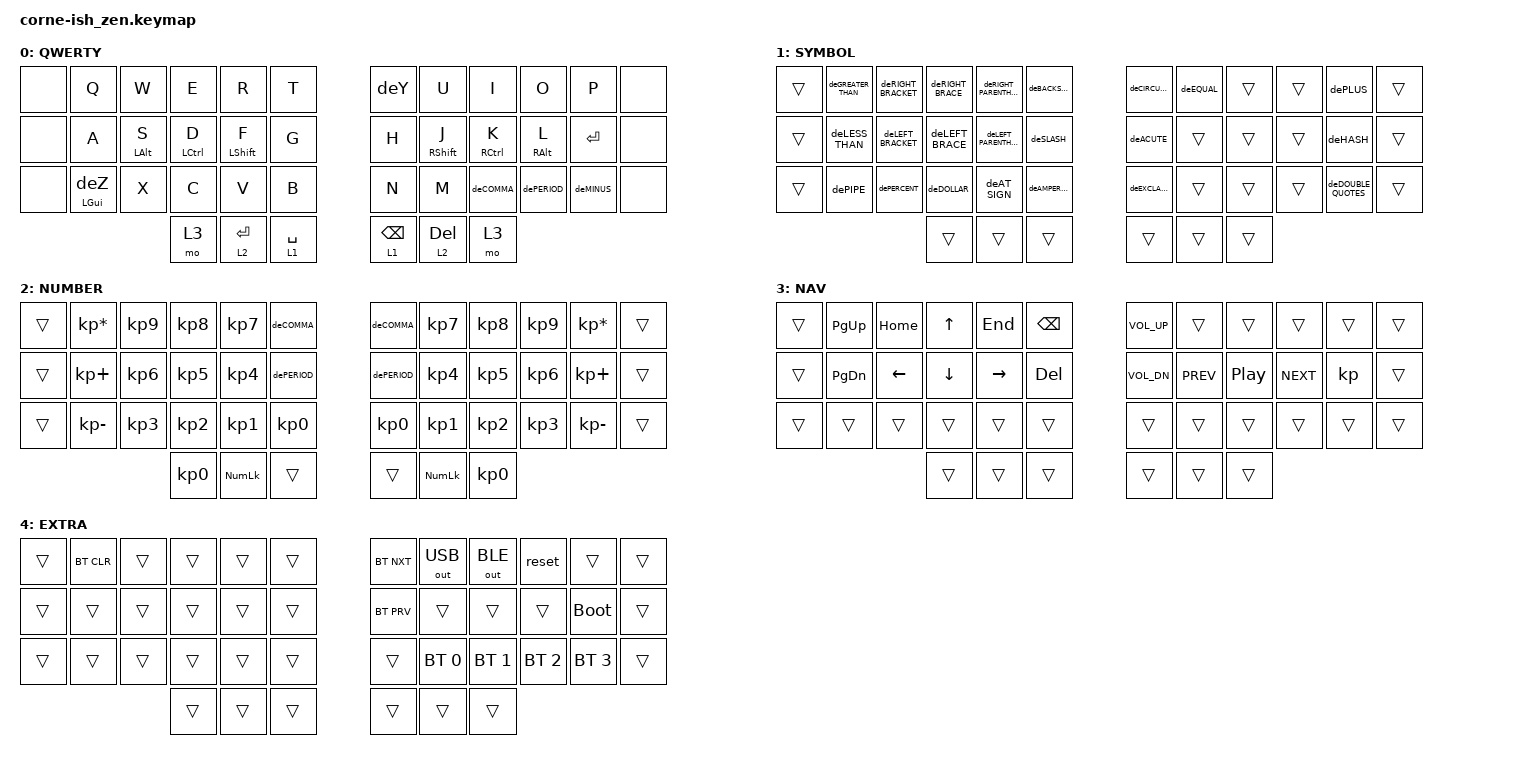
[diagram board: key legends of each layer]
/*
*
* Copyright (c) 2021 Darryl deHaan
* SPDX-License-Identifier: MIT
*
*/

#include <behaviors.dtsi>
#include "language_german.dtsi"
#include <dt-bindings/zmk/keys.h>
#include <dt-bindings/zmk/bt.h>
#include <dt-bindings/zmk/outputs.h>

/ {

	behaviors {
		hm: homerow_mods {
			compatible = "zmk,behavior-hold-tap";
			label = "homerow mods";
			#binding-cells = <2>;
			tapping_term_ms = <200>;
			flavor = "tap-preferred";
			bindings = <&kp>, <&kp>;
		};
	};


	combos {
        compatible = "zmk,combos";
        combo_nav {
            timeout-ms = <40>;
            key-positions = <37 38>;
            bindings = <&tog 3>;
        };
        combo_extra {
            timeout-ms = <40>;
            key-positions = <9 10>;
            bindings = <&tog 4>;
        };

        combo_ue {
            timeout-ms = <40>;
            key-positions = <7 3>;
            bindings = <&kp deUE>;
        };
    	combo_oe {
            timeout-ms = <40>;
            key-positions = <9 3>;
            bindings = <&kp deOE>;
        };
	    combo_ae {
            timeout-ms = <40>;
            key-positions = <13 3>;
            bindings = <&kp deAE>;
        };
        combo_ss {
            timeout-ms = <40>;
            key-positions = <14 15>;
            bindings = <&kp deESZETT>;
        }; 

        combo_esc {
            timeout-ms = <40>;
            key-positions = <16 17>;
            bindings = <&kp ESCAPE>;
        };
        combo_tab {
            timeout-ms = <40>;
            key-positions = <28 29>;
            bindings = <&kp TAB>;
        };

        combo_F1 {
            timeout-ms = <40>;
            key-positions = <1 13>;
            bindings = <&kp F1>;
        };
        combo_F2 {
            timeout-ms = <40>;
            key-positions = <2 14>;
            bindings = <&kp F2>;
        };
        combo_F3 {
            timeout-ms = <40>;
            key-positions = <3 15>;
            bindings = <&kp F3>;
        };
        combo_F4 {
            timeout-ms = <40>;
            key-positions = <4 16>;
            bindings = <&kp F4>;
        };
        combo_F5 {
            timeout-ms = <40>;
            key-positions = <5 17>;
            bindings = <&kp F5>;
        };
        combo_F6 {
            timeout-ms = <40>;
            key-positions = <6 18>;
            bindings = <&kp F6>;
        };
        combo_F7 {
            timeout-ms = <40>;
            key-positions = <7 19>;
            bindings = <&kp F7>;
        };
        combo_F8 {
            timeout-ms = <40>;
            key-positions = <8 20>;
            bindings = <&kp F8>;
        };
        combo_F9 {
            timeout-ms = <40>;
            key-positions = <9 21>;
            bindings = <&kp F1>;
        };
        combo_F10 {
            timeout-ms = <40>;
            key-positions = <10 22>;
            bindings = <&kp F10>;
        };
        combo_F11 {
            timeout-ms = <40>;
            key-positions = <1 2>;
            bindings = <&kp F11>;
        };
        combo_F12 {
            timeout-ms = <40>;
            key-positions = <9 10>;
            bindings = <&kp F12>;
        };

    };
    
        keymap {
                compatible = "zmk,keymap";

                default_layer {
                        label = "QWERTY";
// -----------------------------------------------------------------------------------------
// |      |  Q  |  W  |  E  |  R  |  T  |   |  Y  |  U   |  I  |  O  |  P  |      |
// |      |  A  |  S  |  D  |  F  |  G  |   |  H  |  J   |  K  |  L  |  ;  |      |
// |      |  Z  |  X  |  C  |  V  |  B  |   |  N  |  M   |  ,  |  .  |  /  |      |
//                    |     | LWR | SPC |   | ENT | RSE  |     |
                        bindings = <
// 0     1            2          3           4           5             /**/   6          7           8           9            10          11                   
   &none &kp Q        &kp W      &kp E       &kp R       &kp T         /**/   &kp deY    &kp U       &kp I       &kp O        &kp P       &none
// 12    13           14         15          16          17            /**/   18         19          20          21           22          23
   &none &kp A        &hm LALT S &hm LCTRL D &hm LSHFT F &kp G         /**/   &kp H      &hm RSHFT J &hm RCTRL K &hm RALT L   &kp RET     &none
// 24    25           26         27          28          29            /**/   30         31          32          33           34          35 
   &none &hm LGUI deZ &kp X      &kp C       &kp V       &kp B         /**/   &kp N      &kp M       &kp deCOMMA &kp dePERIOD &kp deMINUS &none
//                               36          37          38            /**/   39         40          41    
                                 &mo 3       &lt 2 RET   &lt 1 SPACE   /**/   &lt 1 BSPC &lt 2 DEL   &mo 3
                        >;
                };
                symbol {
                        label = "SYMBOL";
// -----------------------------------------------------------------------------------------
// |      |  >  |  ]  |  }  |  )  |  \  |   |   ^  |     |     |     |  +  |     |
// |      |  <  |  [  |  {  |  (  |  /  |   |   ´  |     |     |     |  #  |     |
// |      |  |  |  %  |  $  |  @  |  &  |   |   !  |     |     |     |     |     |
//                    |     |     |     |   |      |     |     |
                        bindings = <
   &trans &kp deGREATER_THAN &kp deRIGHT_BRACKET &kp deRIGHT_BRACE &kp  deRIGHT_PARENTHESIS &kp deBACKSLASH /**/  &kp deCIRCUMFLEX  &kp deEQUAL &trans &trans &kp dePLUS          &trans
   &trans &kp deLESS_THAN    &kp deLEFT_BRACKET  &kp deLEFT_BRACE  &kp  deLEFT_PARENTHESIS  &kp deSLASH     /**/  &kp deACUTE       &trans      &trans &trans &kp deHASH          &trans
   &trans &kp dePIPE         &kp dePERCENT       &kp deDOLLAR      &kp  deAT_SIGN           &kp deAMPERSAND /**/  &kp deEXCLAMATION &trans      &trans &trans &kp deDOUBLE_QUOTES &trans
                                                 &trans            &trans                   &trans          /**/  &trans            &trans      &trans 
                        >;
                };

                number {
                        label = "NUMBER";
// -----------------------------------------------------------------------------------------
// |      |  *  |  9  |  8  |  7  |  ,  |   |  ,  |  7  |  8  |  9  |  *  |     |
// |      |  +  |  6  |  5  |  4  |  .  |   |  .  |  4  |  5  |  6  |  +  |     |
// |      |  -  |  3  |  2  |  1  |  0  |   |  0  |  1  |  2  |  3  |  -  |     |
//                    |  0  |NMLCK|     |   |     |NMLCK|  0  |
                        bindings = <
   &trans &kp KP_ASTERISK &kp KP_N9 &kp KP_N8 &kp KP_N7   &kp deCOMMA  &kp deCOMMA  /**/ &kp KP_N7   &kp KP_N8 &kp KP_N9 &kp KP_ASTERISK &trans
   &trans &kp KP_PLUS     &kp KP_N6 &kp KP_N5 &kp KP_N4   &kp dePERIOD &kp dePERIOD /**/ &kp KP_N4   &kp KP_N5 &kp KP_N6 &kp KP_PLUS     &trans
   &trans &kp KP_MINUS    &kp KP_N3 &kp KP_N2 &kp KP_N1   &kp KP_N0    &kp KP_N0    /**/ &kp KP_N1   &kp KP_N2 &kp KP_N3 &kp KP_MINUS    &trans
                                    &kp KP_N0 &kp KP_NLCK &trans       &trans       /**/ &kp KP_NLCK &kp KP_N0
                        >;
                };

                nav {
                        label = "NAV";
// -----------------------------------------------------------------------------------------
// |      | pgup| pos1|  up | end | bspc|   |VOLUP|     |     |     |     |     |
// |      | pgdn| left| down|right| del |   |VOLDN| FFW | PLAY| REW |     |     |
// |      |     |     |     |     |     |   |     |     |     |     |     |     |
//                    |     |     |     |   |     |     |     |
                        bindings = <
   &trans &kp PG_UP &kp HOME &kp UP   &kp END   &kp BSPC  /**/ &kp C_VOL_UP &trans        &trans           &trans     &trans &trans
   &trans &kp PG_DN &kp LEFT &kp DOWN &kp RIGHT &kp DEL   /**/ &kp C_VOL_DN &kp C_PREV &kp C_PLAY_PAUSE &kp C_NEXT &kp    &trans
   &trans &trans    &trans   &trans   &trans    &trans    /**/ &trans       &trans        &trans           &trans     &trans &trans
                             &trans   &trans    &trans    /**/ &trans       &trans        &trans 
                        >;
                };

                extra {
                        label = "EXTRA";
// -----------------------------------------------------------------------------------------
// |      |     |     |     |     |     |   |BT_NXT| USB |  BT |RESET|BT_CLR|     |
// |      |     |     |     |     |     |   |BT_PRV|     |     |     |Boot  |     |
// |      |     |     |     |     |     |   |      | BT 0| BT 1| BT 2| BT 3 |     |
//                    |     |     |     |   |      |     |     |
                        bindings = <
   &trans &bt BT_CLR &trans &trans &trans &trans             &bt BT_NXT &out OUT_USB &out OUT_BLE  &reset   &trans       &trans
   &trans &trans     &trans &trans &trans &trans             &bt BT_PRV &trans       &trans        &trans   &bootloader  &trans
   &trans &trans     &trans &trans &trans &trans             &trans &bt BT_SEL 0 &bt BT_SEL 1  &bt BT_SEL 2 &bt BT_SEL 3 &trans
                            &trans &trans &trans             &trans     &trans       &trans 
                        >;
                };
        };
};
